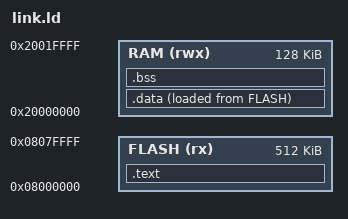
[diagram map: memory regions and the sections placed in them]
ENTRY(Reset_Handler)
_estack = 0x20020000;

MEMORY {
    FLASH (rx)  : ORIGIN = 0x08000000, LENGTH = 512K
    RAM   (rwx) : ORIGIN = 0x20000000, LENGTH = 128K
}

SECTIONS {
    .text : {
        KEEP(*(.isr_vector))
        *(.text*)
        *(.rodata*)
        . = ALIGN(4);
        _etext = .;
    } > FLASH

    .data : {
        . = ALIGN(4);
        _sdata = .;
        *(.data*)
        . = ALIGN(4);
        _edata = .;
    } > RAM AT > FLASH

    .bss : {
        . = ALIGN(4);
        _sbss = .;
        __bss_start__ = _sbss;
        *(.bss*)
        *(COMMON)
        . = ALIGN(4);
        _ebss = .;
        __bss_end__ = _ebss;
    } > RAM

    . = ALIGN(4);
    end = .;
    PROVIDE(end = .);
}
